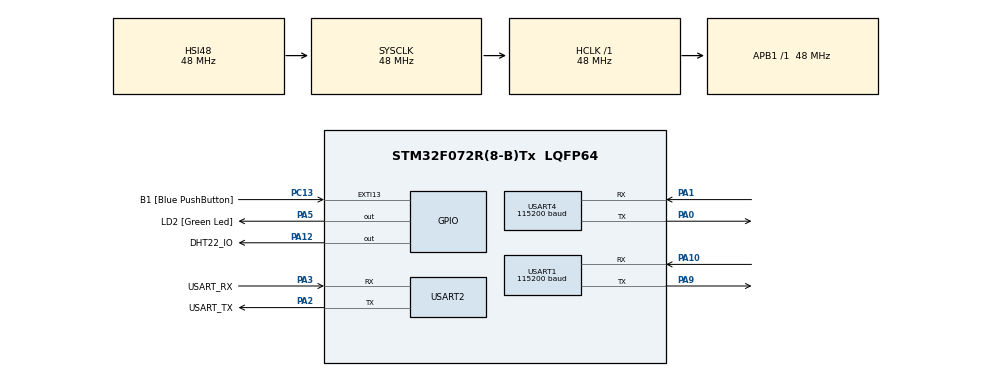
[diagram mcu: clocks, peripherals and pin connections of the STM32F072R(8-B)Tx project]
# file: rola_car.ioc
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FREERTOS.Tasks01=defaultTask,24,128,StartDefaultTask,Default,NULL,Dynamic,NULL,NULL;readDHT22Task,24,128,StartReadDHT22Task,As external,NULL,Dynamic,NULL,NULL;sendRolaDHT22Ta,40,128,StartSendRolaDHT22,As external,NULL,Dynamic,NULL,NULL
Mcu.Family=STM32F0
Mcu.Name=STM32F072R(8-B)Tx
Mcu.Package=LQFP64
NVIC.TIM1_BRK_UP_TRG_COM_IRQn=true\:3\:0\:false\:false\:true\:false\:false\:true
NVIC.TIM7_IRQn=true\:3\:0\:false\:false\:true\:true\:true\:true
NVIC.TimeBase=TIM1_BRK_UP_TRG_COM_IRQn
NVIC.TimeBaseIP=TIM1
NVIC.USART1_IRQn=true\:3\:0\:false\:false\:true\:true\:true\:true
NVIC.USART3_4_IRQn=true\:3\:0\:true\:false\:true\:true\:true\:true
PA0.Mode=Asynchronous
PA0.Signal=USART4_TX
PA1.Mode=Asynchronous
PA1.Signal=USART4_RX
PA10.Mode=Asynchronous
PA10.Signal=USART1_RX
PA12.GPIO_Label=DHT22_IO
PA12.GPIO_PuPd=GPIO_PULLUP
PA12.Signal=GPIO_Output
PA13.GPIO_Label=TMS
PA13.Mode=Serial_Wire
PA13.Signal=SYS_SWDIO
PA14.GPIO_Label=TCK
PA14.Mode=Serial_Wire
PA14.Signal=SYS_SWCLK
PA2.GPIO_Label=USART_TX
PA2.GPIO_Mode=GPIO_MODE_AF_PP
PA2.GPIO_PuPd=GPIO_NOPULL
PA2.GPIO_Speed=GPIO_SPEED_FREQ_LOW
PA2.Mode=Asynchronous
PA2.Signal=USART2_TX
PA3.GPIO_Label=USART_RX
PA3.GPIO_Mode=GPIO_MODE_AF_PP
PA3.GPIO_PuPd=GPIO_NOPULL
PA3.GPIO_Speed=GPIO_SPEED_FREQ_LOW
PA3.Mode=Asynchronous
PA3.Signal=USART2_RX
PA5.GPIO_Label=LD2 [Green Led]
PA5.GPIO_Mode=GPIO_MODE_OUTPUT_PP
PA5.GPIO_PuPd=GPIO_NOPULL
PA5.GPIO_Speed=GPIO_SPEED_FREQ_LOW
PA5.Signal=GPIO_Output
PA9.Mode=Asynchronous
PA9.Signal=USART1_TX
PC13.GPIO_Label=B1 [Blue PushButton]
PC13.GPIO_ModeDefaultEXTI=GPIO_MODE_IT_FALLING
PC13.Signal=GPXTI13
PC14-OSC32_IN.Mode=LSE-External-Oscillator
PC14-OSC32_IN.Signal=RCC_OSC32_IN
PC15-OSC32_OUT.Mode=LSE-External-Oscillator
PC15-OSC32_OUT.Signal=RCC_OSC32_OUT
PF0-OSC_IN.Mode=HSE-External-Clock-Source
PF0-OSC_IN.Signal=RCC_OSC_IN
PF1-OSC_OUT.Signal=RCC_OSC_OUT
ProjectManager.HeapSize=0x200
ProjectManager.StackSize=0x400
ProjectManager.TargetToolchain=MDK-ARM V5.32
RCC.AHBFreq_Value=48000000
RCC.APB1Freq_Value=48000000
RCC.APB1TimFreq_Value=48000000
RCC.FLatency-AdvancedSettings=FLASH_LATENCY_1
RCC.HCLKFreq_Value=48000000
RCC.PLLDivider=RCC_PREDIV_DIV2
RCC.PLLMUL=RCC_PLL_MUL12
RCC.PREFETCH_ENABLE-AdvancedSettings=1
RCC.SYSCLKFreq_VALUE=48000000
RCC.SYSCLKSource=RCC_SYSCLKSOURCE_HSI48
TIM6.Prescaler=48000-1
TIM7.AutoReloadPreload=TIM_AUTORELOAD_PRELOAD_ENABLE
TIM7.Period=100-1
TIM7.Prescaler=480-1
USART1.BaudRate=115200
USART1.VirtualMode-Asynchronous=VM_ASYNC
USART2.VirtualMode=VM_ASYNC
USART2.VirtualMode-Asynchronous=VM_ASYNC
USART4.BaudRate=115200
USART4.VirtualMode-Asynchronous=VM_ASYNC
VP_FREERTOS_VS_CMSIS_V2.Mode=CMSIS_V2
VP_SYS_VS_tim1.Mode=TIM1
VP_TIM6_VS_ClockSourceINT.Mode=Enable_Timer
VP_TIM7_VS_ClockSourceINT.Mode=Enable_Timer
board=NUCLEO-F072RB

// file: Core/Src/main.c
/* USER CODE BEGIN Header */
/**
  ******************************************************************************
  * @file           : main.c
  * @brief          : Main program body
  ******************************************************************************
  * @attention
  *
  * <h2><center>&copy; Copyright (c) 2022 STMicroelectronics.
  * All rights reserved.</center></h2>
  *
  * This software component is licensed by ST under Ultimate Liberty license
  * SLA0044, the "License"; You may not use this file except in compliance with
  * the License. You may obtain a copy of the License at:
  *                             www.st.com/SLA0044
  *
  ******************************************************************************
  */
/* USER CODE END Header */
#include "main.h"
#include "cmsis_os.h"

/* USER CODE BEGIN Includes */
#include <stdio.h>
#include "rola_ctrl.h"
//#include "sensor.h"
#include "my_task.h"

/* USER CODE END Includes */

TIM_HandleTypeDef htim6;
TIM_HandleTypeDef htim7;

UART_HandleTypeDef huart1;
UART_HandleTypeDef huart2;
UART_HandleTypeDef huart4;

/* Definitions for defaultTask */
osThreadId_t defaultTaskHandle;
const osThreadAttr_t defaultTask_attributes = {
  .name = "defaultTask",
  .stack_size = 128 * 4,
  .priority = (osPriority_t) osPriorityNormal,
};
/* Definitions for readDHT22Task */
osThreadId_t readDHT22TaskHandle;
const osThreadAttr_t readDHT22Task_attributes = {
  .name = "readDHT22Task",
  .stack_size = 128 * 4,
  .priority = (osPriority_t) osPriorityNormal,
};
/* Definitions for sendRolaDHT22Ta */
osThreadId_t sendRolaDHT22TaHandle;
const osThreadAttr_t sendRolaDHT22Ta_attributes = {
  .name = "sendRolaDHT22Ta",
  .stack_size = 128 * 4,
  .priority = (osPriority_t) osPriorityHigh,
};
/* USER CODE BEGIN PV */

extern uint8_t rec_data[100];
//extern volatile dht22_data_t dht22_data;
volatile uint32_t timer7_tick;

/* USER CODE END PV */

void SystemClock_Config(void);
static void MX_GPIO_Init(void);
static void MX_USART2_UART_Init(void);
static void MX_USART4_UART_Init(void);
static void MX_USART1_UART_Init(void);
static void MX_TIM6_Init(void);
static void MX_TIM7_Init(void);
void StartDefaultTask(void *argument);
extern void StartReadDHT22Task(void *argument);
extern void StartSendRolaDHT22(void *argument);

/* USER CODE BEGIN 0 */
//	HAL_TIM_Base_Start_IT(&htim7);

/* USER CODE END 0 */

int main(void)
{
  /* USER CODE BEGIN 1 */
	HAL_TIM_Base_Start(&htim7);

  /* USER CODE END 1 */

  /* MCU Configuration--------------------------------------------------------*/

  /* Reset of all peripherals, Initializes the Flash interface and the Systick. */
  HAL_Init();

  /* Configure the system clock */
  SystemClock_Config();

  /* Initialize all configured peripherals */
  MX_GPIO_Init();
  MX_USART2_UART_Init();
  MX_USART4_UART_Init();
  MX_USART1_UART_Init();
  MX_TIM6_Init();
  MX_TIM7_Init();
  /* USER CODE BEGIN 2 */
	rola_init();
  /* USER CODE END 2 */

  /* Init scheduler */
  osKernelInitialize();

  /* Create the thread(s) */
  /* creation of defaultTask */
  defaultTaskHandle = osThreadNew(StartDefaultTask, NULL, &defaultTask_attributes);

  /* creation of readDHT22Task */
  readDHT22TaskHandle = osThreadNew(StartReadDHT22Task, NULL, &readDHT22Task_attributes);

  /* creation of sendRolaDHT22Ta */
  sendRolaDHT22TaHandle = osThreadNew(StartSendRolaDHT22, NULL, &sendRolaDHT22Ta_attributes);

  /* Start scheduler */
  osKernelStart();

  /* We should never get here as control is now taken by the scheduler */
  /* Infinite loop */
  while (1)
  {

  }
}

void SystemClock_Config(void)
{
  RCC_OscInitTypeDef RCC_OscInitStruct = {0};
  RCC_ClkInitTypeDef RCC_ClkInitStruct = {0};
  RCC_PeriphCLKInitTypeDef PeriphClkInit = {0};

  /** Initializes the RCC Oscillators according to the specified parameters
  * in the RCC_OscInitTypeDef structure.
  */
  RCC_OscInitStruct.OscillatorType = RCC_OSCILLATORTYPE_HSI48;
  RCC_OscInitStruct.HSI48State = RCC_HSI48_ON;
  RCC_OscInitStruct.PLL.PLLState = RCC_PLL_NONE;
  if (HAL_RCC_OscConfig(&RCC_OscInitStruct) != HAL_OK)
  {
    Error_Handler();
  }
  /** Initializes the CPU, AHB and APB buses clocks
  */
  RCC_ClkInitStruct.ClockType = RCC_CLOCKTYPE_HCLK|RCC_CLOCKTYPE_SYSCLK
                              |RCC_CLOCKTYPE_PCLK1;
  RCC_ClkInitStruct.SYSCLKSource = RCC_SYSCLKSOURCE_HSI48;
  RCC_ClkInitStruct.AHBCLKDivider = RCC_SYSCLK_DIV1;
  RCC_ClkInitStruct.APB1CLKDivider = RCC_HCLK_DIV1;

  if (HAL_RCC_ClockConfig(&RCC_ClkInitStruct, FLASH_LATENCY_1) != HAL_OK)
  {
    Error_Handler();
  }
  PeriphClkInit.PeriphClockSelection = RCC_PERIPHCLK_USART1|RCC_PERIPHCLK_USART2;
  PeriphClkInit.Usart1ClockSelection = RCC_USART1CLKSOURCE_PCLK1;
  PeriphClkInit.Usart2ClockSelection = RCC_USART2CLKSOURCE_PCLK1;
  if (HAL_RCCEx_PeriphCLKConfig(&PeriphClkInit) != HAL_OK)
  {
    Error_Handler();
  }
}

static void MX_TIM6_Init(void)
{

  TIM_MasterConfigTypeDef sMasterConfig = {0};

  htim6.Instance = TIM6;
  htim6.Init.Prescaler = 48000-1;
  htim6.Init.CounterMode = TIM_COUNTERMODE_UP;
  htim6.Init.Period = 65535;
  htim6.Init.AutoReloadPreload = TIM_AUTORELOAD_PRELOAD_DISABLE;
  if (HAL_TIM_Base_Init(&htim6) != HAL_OK)
  {
    Error_Handler();
  }
  sMasterConfig.MasterOutputTrigger = TIM_TRGO_RESET;
  sMasterConfig.MasterSlaveMode = TIM_MASTERSLAVEMODE_DISABLE;
  if (HAL_TIMEx_MasterConfigSynchronization(&htim6, &sMasterConfig) != HAL_OK)
  {
    Error_Handler();
  }

}

static void MX_TIM7_Init(void)
{

  TIM_MasterConfigTypeDef sMasterConfig = {0};

  htim7.Instance = TIM7;
  htim7.Init.Prescaler = 480-1;
  htim7.Init.CounterMode = TIM_COUNTERMODE_UP;
  htim7.Init.Period = 100-1;
  htim7.Init.AutoReloadPreload = TIM_AUTORELOAD_PRELOAD_ENABLE;
  if (HAL_TIM_Base_Init(&htim7) != HAL_OK)
  {
    Error_Handler();
  }
  sMasterConfig.MasterOutputTrigger = TIM_TRGO_RESET;
  sMasterConfig.MasterSlaveMode = TIM_MASTERSLAVEMODE_DISABLE;
  if (HAL_TIMEx_MasterConfigSynchronization(&htim7, &sMasterConfig) != HAL_OK)
  {
    Error_Handler();
  }
  /* USER CODE BEGIN TIM7_Init 2 */
	TIM7->CR1 |= 0x1ul;
	TIM7->DIER |= 0x1ul;
  /* USER CODE END TIM7_Init 2 */

}

static void MX_USART1_UART_Init(void)
{

  huart1.Instance = USART1;
  huart1.Init.BaudRate = 115200;
  huart1.Init.WordLength = UART_WORDLENGTH_8B;
  huart1.Init.StopBits = UART_STOPBITS_1;
  huart1.Init.Parity = UART_PARITY_NONE;
  huart1.Init.Mode = UART_MODE_TX_RX;
  huart1.Init.HwFlowCtl = UART_HWCONTROL_NONE;
  huart1.Init.OverSampling = UART_OVERSAMPLING_16;
  huart1.Init.OneBitSampling = UART_ONE_BIT_SAMPLE_DISABLE;
  huart1.AdvancedInit.AdvFeatureInit = UART_ADVFEATURE_NO_INIT;
  if (HAL_UART_Init(&huart1) != HAL_OK)
  {
    Error_Handler();
  }

}

static void MX_USART2_UART_Init(void)
{

  huart2.Instance = USART2;
  huart2.Init.BaudRate = 38400;
  huart2.Init.WordLength = UART_WORDLENGTH_8B;
  huart2.Init.StopBits = UART_STOPBITS_1;
  huart2.Init.Parity = UART_PARITY_NONE;
  huart2.Init.Mode = UART_MODE_TX_RX;
  huart2.Init.HwFlowCtl = UART_HWCONTROL_NONE;
  huart2.Init.OverSampling = UART_OVERSAMPLING_16;
  huart2.Init.OneBitSampling = UART_ONE_BIT_SAMPLE_DISABLE;
  huart2.AdvancedInit.AdvFeatureInit = UART_ADVFEATURE_NO_INIT;
  if (HAL_UART_Init(&huart2) != HAL_OK)
  {
    Error_Handler();
  }

}

static void MX_USART4_UART_Init(void)
{

  huart4.Instance = USART4;
  huart4.Init.BaudRate = 115200;
  huart4.Init.WordLength = UART_WORDLENGTH_8B;
  huart4.Init.StopBits = UART_STOPBITS_1;
  huart4.Init.Parity = UART_PARITY_NONE;
  huart4.Init.Mode = UART_MODE_TX_RX;
  huart4.Init.HwFlowCtl = UART_HWCONTROL_NONE;
  huart4.Init.OverSampling = UART_OVERSAMPLING_16;
  huart4.Init.OneBitSampling = UART_ONE_BIT_SAMPLE_DISABLE;
  huart4.AdvancedInit.AdvFeatureInit = UART_ADVFEATURE_NO_INIT;
  if (HAL_UART_Init(&huart4) != HAL_OK)
  {
    Error_Handler();
  }

}

static void MX_GPIO_Init(void)
{
  GPIO_InitTypeDef GPIO_InitStruct = {0};

  /* GPIO Ports Clock Enable */
  __HAL_RCC_GPIOC_CLK_ENABLE();
  __HAL_RCC_GPIOF_CLK_ENABLE();
  __HAL_RCC_GPIOA_CLK_ENABLE();

  /*Configure GPIO pin Output Level */
  HAL_GPIO_WritePin(GPIOA, LD2_Pin|DHT22_IO_Pin, GPIO_PIN_RESET);

  /*Configure GPIO pin : B1_Pin */
  GPIO_InitStruct.Pin = B1_Pin;
  GPIO_InitStruct.Mode = GPIO_MODE_IT_FALLING;
  GPIO_InitStruct.Pull = GPIO_NOPULL;
  HAL_GPIO_Init(B1_GPIO_Port, &GPIO_InitStruct);

  /*Configure GPIO pin : LD2_Pin */
  GPIO_InitStruct.Pin = LD2_Pin;
  GPIO_InitStruct.Mode = GPIO_MODE_OUTPUT_PP;
  GPIO_InitStruct.Pull = GPIO_NOPULL;
  GPIO_InitStruct.Speed = GPIO_SPEED_FREQ_LOW;
  HAL_GPIO_Init(LD2_GPIO_Port, &GPIO_InitStruct);

  /*Configure GPIO pin : DHT22_IO_Pin */
  GPIO_InitStruct.Pin = DHT22_IO_Pin;
  GPIO_InitStruct.Mode = GPIO_MODE_OUTPUT_PP;
  GPIO_InitStruct.Pull = GPIO_PULLUP;
  GPIO_InitStruct.Speed = GPIO_SPEED_FREQ_LOW;
  HAL_GPIO_Init(DHT22_IO_GPIO_Port, &GPIO_InitStruct);

}

void StartDefaultTask(void *argument)
{
  /* USER CODE BEGIN 5 */
  /* Infinite loop */
  for(;;)
  {
    osDelay(1000);
//		char buffer[100];
//		sprintf(buffer, "{\"temp\": \"%0.2f\", \"humd\": \"%0.2f\"", dht22_data.temperature, dht22_data.humdity);

//
//		printf("buffer: %s\r\n", buffer);
//		show_now_data();

  }
  /* USER CODE END 5 */
}

void HAL_TIM_PeriodElapsedCallback(TIM_HandleTypeDef *htim)
{
  if (htim->Instance == TIM1) {
    HAL_IncTick();
  }
}

void Error_Handler(void)
{
  __disable_irq();
  while (1)
  {
  }
}

/************************ (C) COPYRIGHT STMicroelectronics *****END OF FILE****/
